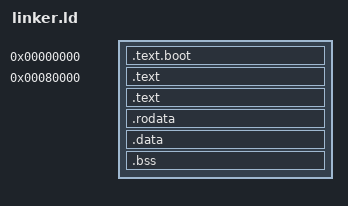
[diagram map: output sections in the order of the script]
/*
 * Copyright (C) 2018 bzt (bztsrc@github)
 *
 * Permission is hereby granted, free of charge, to any person
 * obtaining a copy of this software and associated documentation
 * files (the "Software"), to deal in the Software without
 * restriction, including without limitation the rights to use, copy,
 * modify, merge, publish, distribute, sublicense, and/or sell copies
 * of the Software, and to permit persons to whom the Software is
 * furnished to do so, subject to the following conditions:
 *
 * The above copyright notice and this permission notice shall be
 * included in all copies or substantial portions of the Software.
 *
 * THE SOFTWARE IS PROVIDED "AS IS", WITHOUT WARRANTY OF ANY KIND,
 * EXPRESS OR IMPLIED, INCLUDING BUT NOT LIMITED TO THE WARRANTIES OF
 * MERCHANTABILITY, FITNESS FOR A PARTICULAR PURPOSE AND
 * NONINFRINGEMENT. IN NO EVENT SHALL THE AUTHORS OR COPYRIGHT
 * HOLDERS BE LIABLE FOR ANY CLAIM, DAMAGES OR OTHER LIABILITY,
 * WHETHER IN AN ACTION OF CONTRACT, TORT OR OTHERWISE, ARISING FROM,
 * OUT OF OR IN CONNECTION WITH THE SOFTWARE OR THE USE OR OTHER
 * DEALINGS IN THE SOFTWARE.
 *
 */

SECTIONS
{
    . = 0x0;
    .text.boot : {
        *(.text.boot)
    }
    
    . = 0x80000;
    .text : {
        *(.text .text.*)
    }

    /* start of the binary */
    __text_beg = .;

    .text : {
        KEEP(*(.text.boot))
        *(.text._start)
        KEEP(*(.text.vectors))   /* Include and keep the vectors section */
        *(.text .text.* .gnu.linkonce.t*)
    }

    .rodata : {
        *(.rodata .rodata.* .gnu.linkonce.r*)
    }

    PROVIDE(_data = .);
    .data : {
        *(.data .data.* .gnu.linkonce.d*)
    }

    .bss (NOLOAD) : {
        . = ALIGN(32);
        __bss_beg = .;
        *(.bss .bss.*)
        *(COMMON)
        . = ALIGN(8);
        __bss_end = .;
    }

    /* end of the binary */
    __text_end = ALIGN(8);

    /* number of bytes in BSS section and complete binary */
    __bss_len = (__bss_end - __bss_beg);
    __text_len = (__text_end - __text_beg);

    _end = .;

    /DISCARD/ : { *(.comment) *(.gnu*) *(.note*) *(.eh_frame*) }
}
